# STM32G554xx register map
File version: 1.0
Registers are 32-bit, read-write, reset 0x0 unless marked. A register's access mark holds for its fields unless they carry their own. Offsets are from the block's base; [hi:lo] are bit positions; {n}, {i} and the like mark numbered series; 'fields as' and 'values as' point back to an identical list.

## USB_DRD_PMA_BUFF — Universal Serial Bus PacketMemoryArea Buffer Descriptor Table
Base 0x40016400
0x00 TXBD — Channel/endpoint transmit buffer descriptor
0x04 RXBD — Channel/endpoint receive buffer descriptor

## CRC — Cyclic redundancy check calculation unit (CRC)
Base 0x40023000
0x00 DR — CRC data register
  [31:0] DR — Data register bits
0x04 IDR — CRC independent data register
  [31:0] IDR — General-purpose 32-bit data register bits
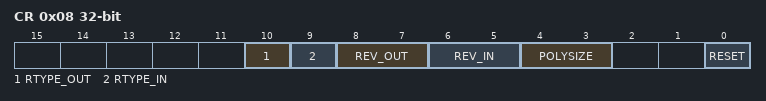
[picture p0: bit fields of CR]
0x08 CR — CRC control register
  [10] RTYPE_OUT — Reverse type output
  [9] RTYPE_IN — Reverse type input
  [8:7] REV_OUT — Reverse output data
  [6:5] REV_IN — Reverse input data
  [4:3] POLYSIZE — Polynomial size
  [0] RESET — RESET bit
0x10 INIT — CRC initial value
  [31:0] CRC_INIT — Programmable initial CRC value
0x14 POL — CRC polynomial
  [31:0] POL — Programmable polynomial

## CORDIC1 — CORDIC coprocessor (CORDIC)
Base 0x40023800
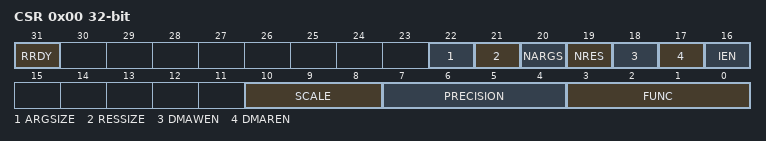
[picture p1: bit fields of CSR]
0x00 CSR — CORDIC Control and Status register
  [31] RRDY — Result ready flag
  [22] ARGSIZE — Width of input data
  [21] RESSIZE — Width of output data
  [20] NARGS
  [19] NRES
  [18] DMAWEN — Enable DMA write channel
  [17] DMAREN — Enable DMA read channel
  [16] IEN — Enable interrupt
  [10:8] SCALE — Scaling factor
  [7:4] PRECISION — Precision required (number of iterations)
  [3:0] FUNC — Function
0x04 WDATA — CORDIC argument register
  [31:0] ARG — Function input arguments
0x08 RDATA ro — CORDIC result register
  [31:0] RES — Function result

## FMAC1 — Filter math accelerator (FMAC)
Base 0x40023C00
Same registers: FMAC2 0x42024400
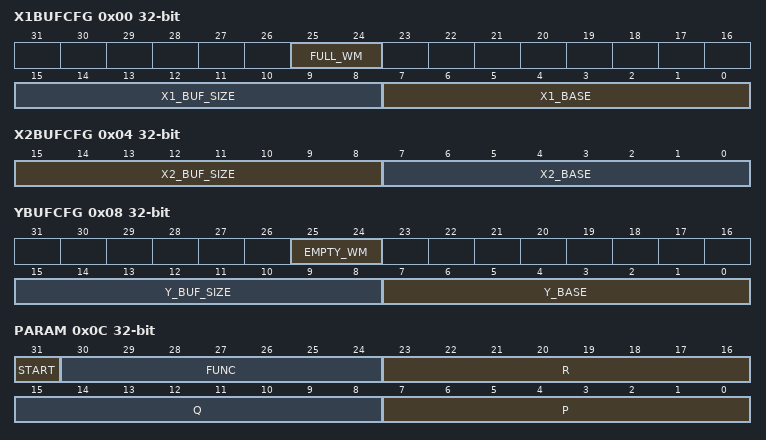
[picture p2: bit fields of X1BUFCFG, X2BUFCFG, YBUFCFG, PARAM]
0x00 X1BUFCFG — FMAC X1 buffer configuration register
  [25:24] FULL_WM — Watermark for buffer full flag
  [15:8] X1_BUF_SIZE
  [7:0] X1_BASE — Base address of X1 buffer
0x04 X2BUFCFG — FMAC X2 buffer configuration register
  [15:8] X2_BUF_SIZE
  [7:0] X2_BASE — Base address of X2 buffer
0x08 YBUFCFG — FMAC Y buffer configuration register
  [25:24] EMPTY_WM — Watermark for buffer empty flag
  [15:8] Y_BUF_SIZE
  [7:0] Y_BASE — Base address of Y buffer
0x0C PARAM — FMAC parameter register
  [31] START — Enable execution
  [30:24] FUNC — Function
  [23:16] R — Input parameter R
  [15:8] Q — Input parameter Q
  [7:0] P — Input parameter P
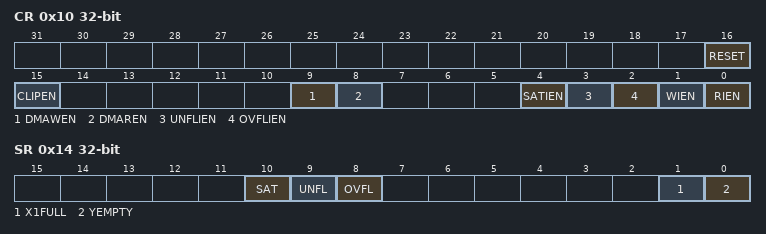
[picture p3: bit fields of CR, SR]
0x10 CR — FMAC control register
  [16] RESET — Reset FMAC unit
  [15] CLIPEN — Enable clipping
  [9] DMAWEN
  [8] DMAREN
  [4] SATIEN
  [3] UNFLIEN
  [2] OVFLIEN
  [1] WIEN — Enable write interrupt
  [0] RIEN — Enable read interrupt
0x14 SR ro — FMAC status register
  [10] SAT — Saturation error flag
  [9] UNFL — Underflow error flag
  [8] OVFL — Overflow error flag
  [1] X1FULL — X1 buffer full flag
  [0] YEMPTY — Y buffer empty flag
0x18 WDATA — FMAC write data register
  [15:0] WDATA — Write data
0x1C RDATA ro — FMAC read data register
  [15:0] RDATA — Read data

## RAMCFG
Base 0x40026000
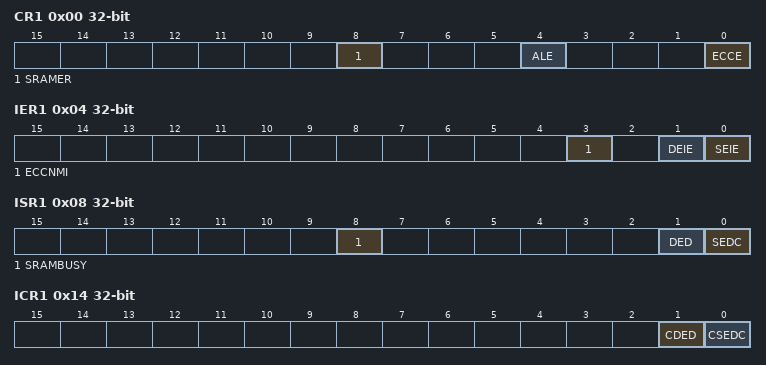
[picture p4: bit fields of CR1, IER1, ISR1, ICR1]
0x00 CR1 — RAMCFG control register
  [8] SRAMER — SRAM erase
  [4] ALE — Address latch enable
  [0] ECCE — ECC enable
0x04 IER1 — RAMCFG interrupt enable register
  [3] ECCNMI — Double error NMI
  [1] DEIE — ECC double error interrupt enable
  [0] SEIE — ECC single error interrupt enable
0x08 ISR1 ro — RAMCFG interrupt status register
  [8] SRAMBUSY — SRAM busy with erase operation
  [1] DED — ECC double error detected
  [0] SEDC
0x0C SEAR1 ro — RAMCFG ECC single error address register
  [31:0] ESEA — ECC single error address
0x10 DEAR1 ro — RAMCFG ECC double error address register
  [31:0] EDEA — ECC double error address
0x14 ICR1 — RAMCFG interrupt clear register 1
  [1] CDED — Clear ECC double error detected
  [0] CSEDC
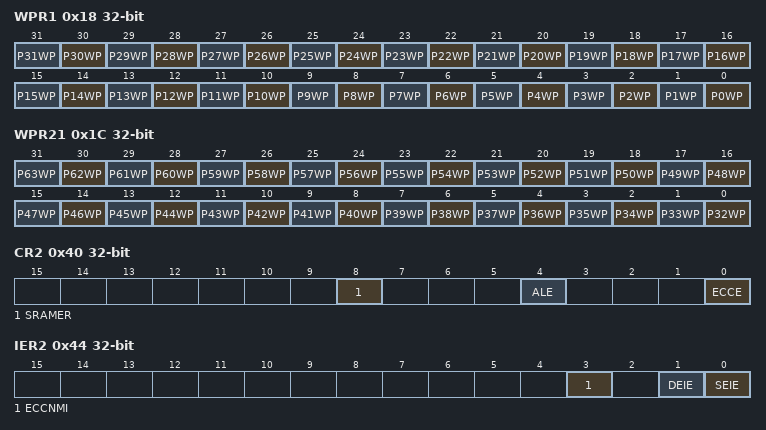
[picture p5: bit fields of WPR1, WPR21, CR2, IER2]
0x18 WPR1 — RAMCFG write protection register 1
  [n] P{n}WP (n=0..31) — SRAM2 1-Kbyte page y write protection
0x1C WPR21 — RAMCFG write protection register 2
  [n-32] P{n}WP (n=32..63) — SRAM2 1-Kbyte page y write protection
0x24 ECCKEYR1 — RAMCFG ECC key register
  [7:0] ECCKEY — ECC write protection key
0x28 ERKEYR1 — RAMCFG erase key register
  [7:0] ERASEKEY — Erase write protection key
0x40 CR2 — RAMCFG control register
  fields as CR1
0x44 IER2 — RAMCFG interrupt enable register
  fields as IER1
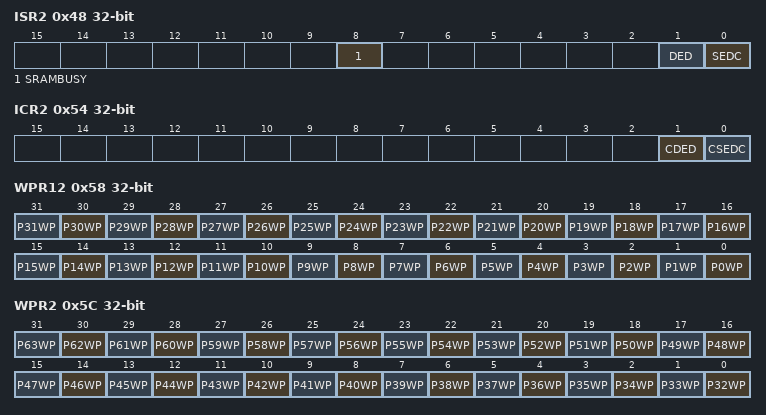
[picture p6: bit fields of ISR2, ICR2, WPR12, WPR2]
0x48 ISR2 ro — RAMCFG interrupt status register
  fields as ISR1
0x4C SEAR2 ro — RAMCFG ECC single error address register
  [31:0] ESEA — ECC single error address
0x50 DEAR2 ro — RAMCFG ECC double error address register
  [31:0] EDEA — ECC double error address
0x54 ICR2 — RAMCFG interrupt clear register 1
  [1] CDED — Clear ECC double error detected
  [0] CSEDC
0x58 WPR12 — RAMCFG write protection register 1
  [n] P{n}WP (n=0..31) — SRAM2 1-Kbyte page y write protection
0x5C WPR2 — RAMCFG write protection register 2
  [n-32] P{n}WP (n=32..63) — SRAM2 1-Kbyte page y write protection
0x64 ECCKEYR2 — RAMCFG ECC key register
  [7:0] ECCKEY — ECC write protection key
0x68 ERKEYR2 — RAMCFG erase key register
  [7:0] ERASEKEY — Erase write protection key
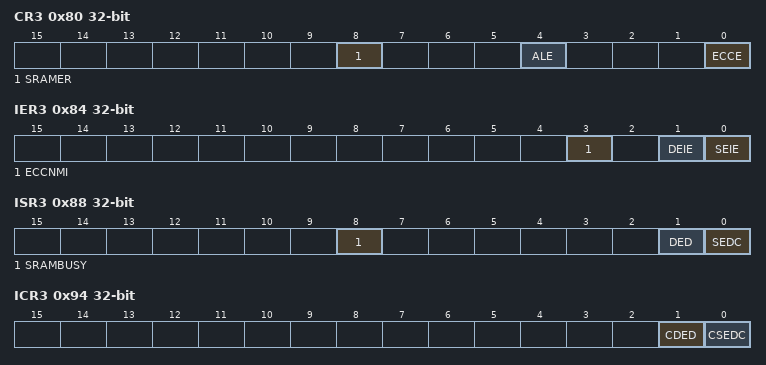
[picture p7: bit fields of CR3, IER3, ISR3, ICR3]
0x80 CR3 — RAMCFG control register
  fields as CR1
0x84 IER3 — RAMCFG interrupt enable register
  fields as IER1
0x88 ISR3 ro — RAMCFG interrupt status register
  fields as ISR1
0x8C SEAR3 ro — RAMCFG ECC single error address register
  [31:0] ESEA — ECC single error address
0x90 DEAR3 ro — RAMCFG ECC double error address register
  [31:0] EDEA — ECC double error address
0x94 ICR3 — RAMCFG interrupt clear register 1
  [1] CDED — Clear ECC double error detected
  [0] CSEDC
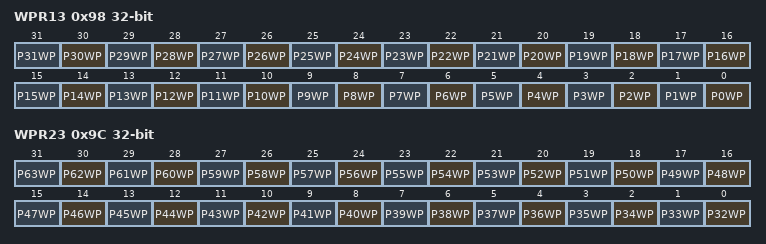
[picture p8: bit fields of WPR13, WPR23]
0x98 WPR13 — RAMCFG write protection register 1
  [n] P{n}WP (n=0..31) — SRAM2 1-Kbyte page y write protection
0x9C WPR23 — RAMCFG write protection register 2
  [n-32] P{n}WP (n=32..63) — SRAM2 1-Kbyte page y write protection
0xA4 ECCKEYR3 — RAMCFG ECC key register
  [7:0] ECCKEY — ECC write protection key
0xA8 ERKEYR3 — RAMCFG erase key register
  [7:0] ERASEKEY — Erase write protection key
